# STM32U5Gx register map
File version: 1.0
CPU: CM33 r0p1, little endian, MPU, FPU, 4 interrupt priority bits
Registers are 32-bit, read-write, reset 0x0 unless marked. A register's access mark holds for its fields unless they carry their own. Offsets are from the block's base; [hi:lo] are bit positions; {n}, {i} and the like mark numbered series; 'fields as' and 'values as' point back to an identical list.

## OTG_HS
Base 0x42040000
Same registers: SEC_OTG_HS 0x52040000
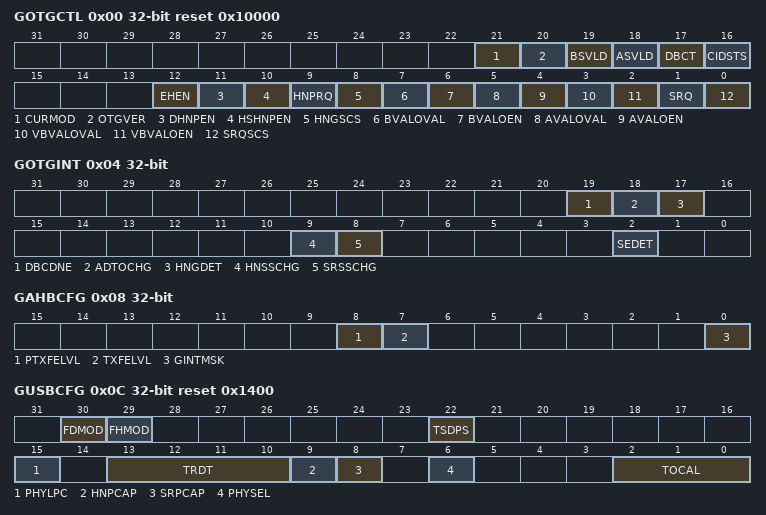
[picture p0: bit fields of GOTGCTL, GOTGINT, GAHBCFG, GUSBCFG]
0x00 GOTGCTL access per field reset 0x10000 — The GOTGCTL register controls the behavior and reflects the status of the OTG function of the core.
  [21] CURMOD ro, [20] OTGVER rw, [19] BSVLD ro, [18] ASVLD ro, [17] DBCT ro, [16] CIDSTS ro, [12] EHEN rw, [11] DHNPEN rw, [10] HSHNPEN rw, [9] HNPRQ rw, [8] HNGSCS ro, [7] BVALOVAL rw, [6] BVALOEN rw, [5] AVALOVAL rw, [4] AVALOEN rw, [3] VBVALOVAL rw, [2] VBVALOEN rw, [1] SRQ rw, [0] SRQSCS ro
0x04 GOTGINT — The application reads this register whenever there is an OTG interrupt and clears the bits in this register to clear the OTG interrupt.
  [19] DBCDNE, [18] ADTOCHG, [17] HNGDET, [9] HNSSCHG, [8] SRSSCHG, [2] SEDET
0x08 GAHBCFG — This register can be used to configure the core after power-on or a change in mode. This register mainly contains AHB system-related configuration parameters. Do not change this register after the initial programming. The application must program this register before starting any transactions on either the AHB or the USB.
  [8] PTXFELVL, [7] TXFELVL, [0] GINTMSK
0x0C GUSBCFG access per field reset 0x1400 — This register can be used to configure the core after power-on or a changing to host mode or device mode. It contains USB and USB-PHY related configuration parameters. The application must program this register before starting any transactions on either the AHB or the USB. Do not make changes to this register after the initial programming.
  [30] FDMOD rw, [29] FHMOD rw, [22] TSDPS rw, [15] PHYLPC rw, [13:10] TRDT rw, [9] HNPCAP rw, [8] SRPCAP rw, [6] PHYSEL ro, [2:0] TOCAL rw
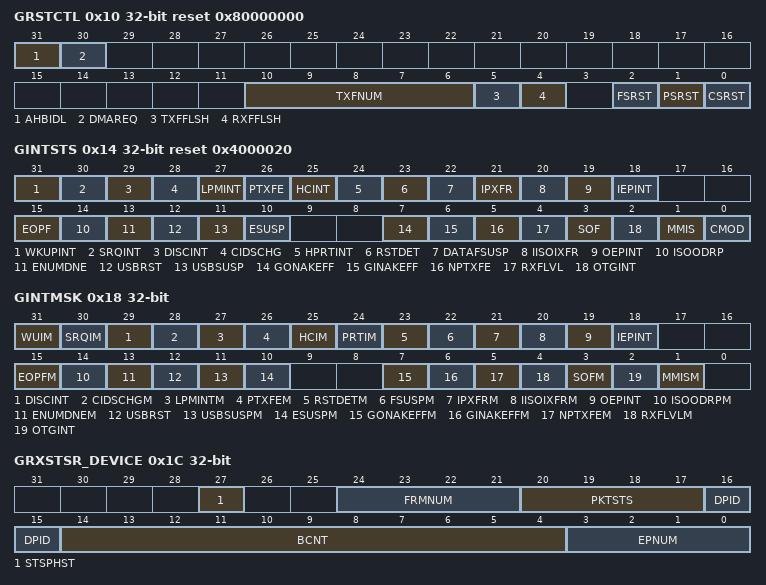
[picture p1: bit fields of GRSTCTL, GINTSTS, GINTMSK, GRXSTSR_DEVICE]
0x10 GRSTCTL access per field reset 0x80000000 — The application uses this register to reset various hardware features inside the core.
  [31] AHBIDL ro, [30] DMAREQ ro, [10:6] TXFNUM rw, [5] TXFFLSH rw, [4] RXFFLSH rw, [2] FSRST rw, [1] PSRST rw, [0] CSRST ro
0x14 GINTSTS access per field reset 0x4000020 — This register interrupts the application for system-level events in the current mode (device mode or host mode). Some of the bits in this register are valid only in host mode, while others are valid in device mode only. This register also indicates the current mode. To clear the interrupt status bits of the rc_w1 type, the application must write 1 into the bit. The FIFO status interrupts are read-only; once software reads from or writes to the FIFO while servicing these interrupts, FIFO interrupt conditions are cleared automatically. The application must clear the GINTSTS register at initialization before unmasking the interrupt bit to avoid any interrupts generated prior to initialization.
  [31] WKUPINT rw, [30] SRQINT rw, [29] DISCINT rw, [28] CIDSCHG rw, [27] LPMINT rw, [26] PTXFE ro, [25] HCINT ro, [24] HPRTINT ro, [23] RSTDET rw, [22] DATAFSUSP rw, [21] IPXFR rw, [20] IISOIXFR rw, [19] OEPINT ro, [18] IEPINT ro, [15] EOPF rw, [14] ISOODRP rw, [13] ENUMDNE rw, [12] USBRST rw, [11] USBSUSP rw, [10] ESUSP rw, [7] GONAKEFF ro, [6] GINAKEFF ro, [5] NPTXFE ro, [4] RXFLVL ro, [3] SOF rw, [2] OTGINT ro, [1] MMIS rw, [0] CMOD ro
0x18 GINTMSK — This register works with the core interrupt register to interrupt the application. When an interrupt bit is masked, the interrupt associated with that bit is not generated. However, the core interrupt (GINTSTS) register bit corresponding to that interrupt is still set.
  [31] WUIM, [30] SRQIM, [29] DISCINT, [28] CIDSCHGM, [27] LPMINTM, [26] PTXFEM, [25] HCIM, [24] PRTIM, [23] RSTDETM, [22] FSUSPM, [21] IPXFRM, [20] IISOIXFRM, [19] OEPINT, [18] IEPINT, [15] EOPFM, [14] ISOODRPM, [13] ENUMDNEM, [12] USBRST, [11] USBSUSPM, [10] ESUSPM, [7] GONAKEFFM, [6] GINAKEFFM, [5] NPTXFEM, [4] RXFLVLM, [3] SOFM, [2] OTGINT, [1] MMISM
0x1C GRXSTSR_DEVICE ro — This description is for register GRXSTSR in Device mode. A read to the receive status debug read register returns the contents of the top of the receive FIFO. The core ignores the receive status read when the receive FIFO is empty and returns a value of 0x00000000.
  [27] STSPHST, [24:21] FRMNUM, [20:17] PKTSTS, [16:15] DPID, [14:4] BCNT, [3:0] EPNUM
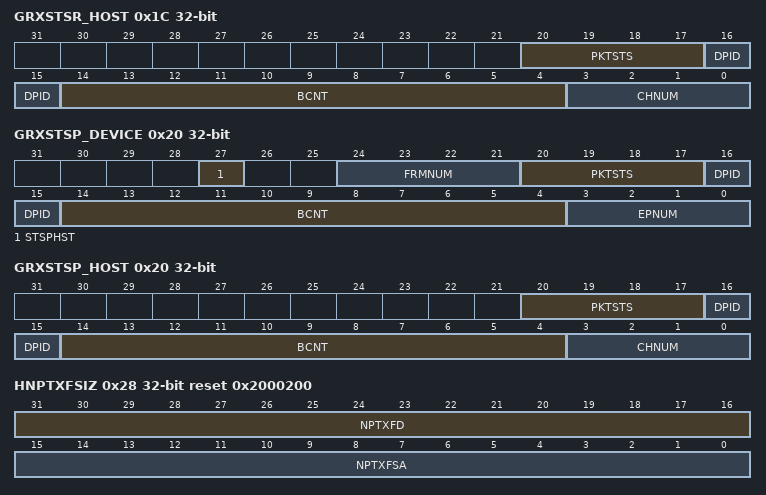
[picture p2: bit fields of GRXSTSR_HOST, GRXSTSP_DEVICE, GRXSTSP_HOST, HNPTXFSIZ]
0x1C GRXSTSR_HOST ro (alternate view of GRXSTSR_DEVICE) — This description is for register GRXSTSR in Host mode
  [20:17] PKTSTS, [16:15] DPID, [14:4] BCNT, [3:0] CHNUM
0x20 GRXSTSP_DEVICE ro — This description is for register GRXSTSP in Device mode. Similarly to GRXSTSR (receive status debug read register) where a read returns the contents of the top of the receive FIFO, a read to GRXSTSP (receive status read and pop register) additionally pops the top data entry out of the Rx FIFO. The core ignores the receive status pop/read when the receive FIFO is empty and returns a value of 0x00000000. The application must only pop the receive status FIFO when the receive FIFO non-empty bit of the core interrupt register (RXFLVL bit in GINTSTS) is asserted.
  fields as GRXSTSR_DEVICE
0x20 GRXSTSP_HOST ro (alternate view of GRXSTSP_DEVICE) — This description is for register GRXSTSP in HOST mode
  [20:17] PKTSTS, [16:15] DPID, [14:4] BCNT, [3:0] CHNUM
0x24 GRXFSIZ reset 0x400 — The application can program the RAM size that must be allocated to the Rx FIFO.
  [15:0] RXFD
0x28 HNPTXFSIZ reset 0x2000200 — Host mode
  [31:16] NPTXFD, [15:0] NPTXFSA
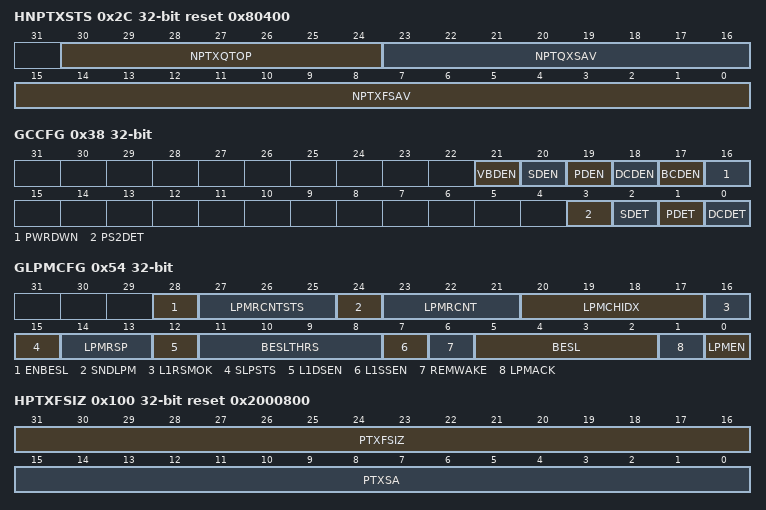
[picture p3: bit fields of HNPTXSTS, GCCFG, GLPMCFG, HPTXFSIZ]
0x2C HNPTXSTS ro reset 0x80400 — In device mode, this register is not valid. This read-only register contains the free space information for the non-periodic Tx FIFO and the non-periodic transmit request queue.
  [30:24] NPTXQTOP, [23:16] NPTQXSAV, [15:0] NPTXFSAV
0x38 GCCFG access per field — OTG general core configuration register
  [21] VBDEN rw, [20] SDEN rw, [19] PDEN rw, [18] DCDEN rw, [17] BCDEN rw, [16] PWRDWN rw, [3] PS2DET ro, [2] SDET ro, [1] PDET ro, [0] DCDET ro
0x3C CID reset 0x3100 — This is a register containing the Product ID as reset value.
  [31:0] PRODUCT_ID
0x54 GLPMCFG access per field — OTG core LPM configuration register
  [28] ENBESL rw, [27:25] LPMRCNTSTS ro, [24] SNDLPM rw, [23:21] LPMRCNT rw, [20:17] LPMCHIDX rw, [16] L1RSMOK ro, [15] SLPSTS ro, [14:13] LPMRSP ro, [12] L1DSEN rw, [11:8] BESLTHRS rw, [7] L1SSEN rw, [6] REMWAKE rw, [5:2] BESL rw, [1] LPMACK rw, [0] LPMEN rw
0x100 HPTXFSIZ reset 0x2000800 — OTG host periodic transmit FIFO size register
  [31:16] PTXFSIZ, [15:0] PTXSA
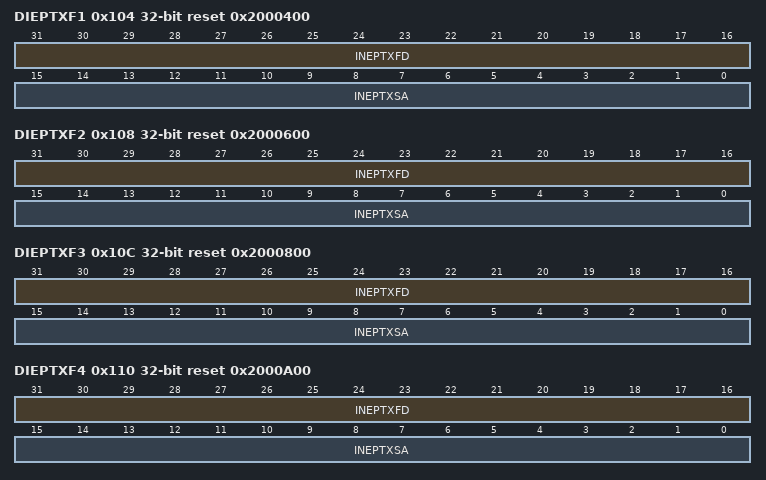
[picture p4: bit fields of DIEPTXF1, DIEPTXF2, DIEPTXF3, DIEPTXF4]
0x104 DIEPTXF1 reset 0x2000400 — OTG device IN endpoint transmit FIFO 1 size register
  [31:16] INEPTXFD, [15:0] INEPTXSA
0x108 DIEPTXF2 reset 0x2000600 — OTG device IN endpoint transmit FIFO 2 size register
  [31:16] INEPTXFD, [15:0] INEPTXSA
0x10C DIEPTXF3 reset 0x2000800 — OTG device IN endpoint transmit FIFO 3 size register
  [31:16] INEPTXFD, [15:0] INEPTXSA
0x110 DIEPTXF4 reset 0x2000A00 — OTG device IN endpoint transmit FIFO 4 size register
  [31:16] INEPTXFD, [15:0] INEPTXSA
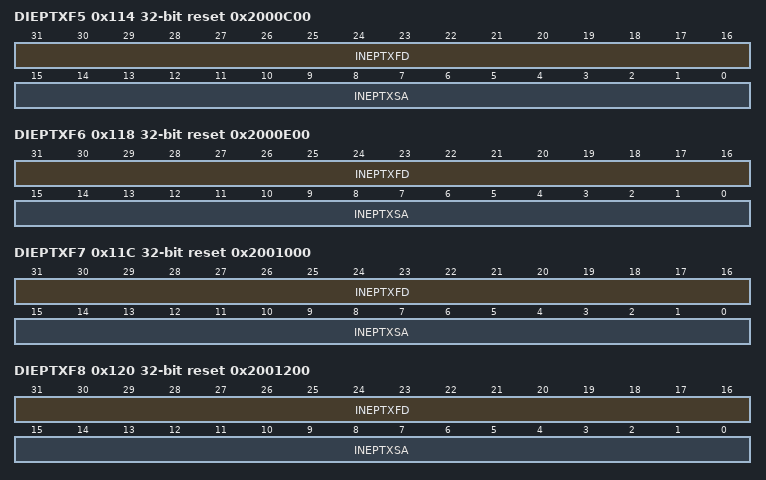
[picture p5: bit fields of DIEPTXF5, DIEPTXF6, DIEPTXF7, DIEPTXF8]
0x114 DIEPTXF5 reset 0x2000C00 — OTG device IN endpoint transmit FIFO 5 size register
  [31:16] INEPTXFD, [15:0] INEPTXSA
0x118 DIEPTXF6 reset 0x2000E00 — OTG device IN endpoint transmit FIFO 6 size register
  [31:16] INEPTXFD, [15:0] INEPTXSA
0x11C DIEPTXF7 reset 0x2001000 — OTG device IN endpoint transmit FIFO 7 size register
  [31:16] INEPTXFD, [15:0] INEPTXSA
0x120 DIEPTXF8 reset 0x2001200 — OTG device IN endpoint transmit FIFO 8 size register
  [31:16] INEPTXFD, [15:0] INEPTXSA
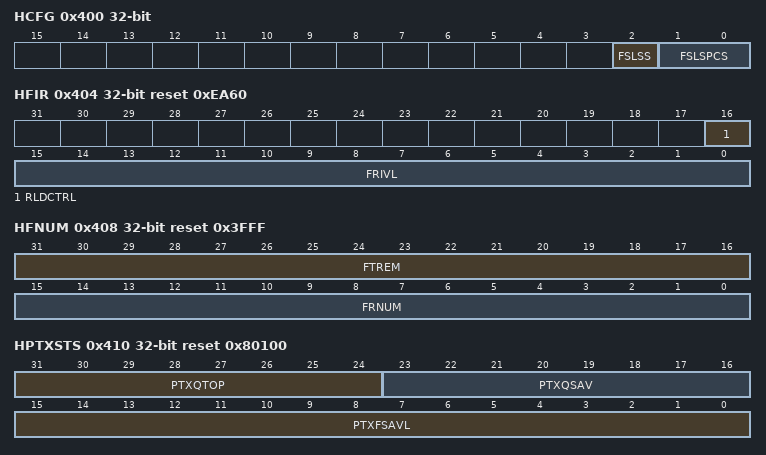
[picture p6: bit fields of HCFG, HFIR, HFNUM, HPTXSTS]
0x400 HCFG access per field — This register configures the core after power-on. Do not make changes to this register after initializing the host.
  [2] FSLSS ro, [1:0] FSLSPCS rw
0x404 HFIR reset 0xEA60 — This register stores the frame interval information for the current speed to which the OTG controller has enumerated.
  [16] RLDCTRL, [15:0] FRIVL
0x408 HFNUM ro reset 0x3FFF — This register indicates the current frame number. It also indicates the time remaining (in terms of the number of PHY clocks) in the current frame.
  [31:16] FTREM, [15:0] FRNUM
0x410 HPTXSTS ro reset 0x80100 — This read-only register contains the free space information for the periodic Tx FIFO and the periodic transmit request queue.
  [31:24] PTXQTOP, [23:16] PTXQSAV, [15:0] PTXFSAVL
0x414 HAINT ro — When a significant event occurs on a channel, the host all channels interrupt register interrupts the application using the host channels interrupt bit of the core interrupt register (HCINT bit in GINTSTS). This is shown in Figure724. There is one interrupt bit per channel, up to a maximum of 16 bits. Bits in this register are set and cleared when the application sets and clears bits in the corresponding host channel-x interrupt register.
  [15:0] HAINT
0x418 HAINTMSK — The host all channel interrupt mask register works with the host all channel interrupt register to interrupt the application when an event occurs on a channel. There is one interrupt mask bit per channel, up to a maximum of 16 bits.
  [15:0] HAINTM
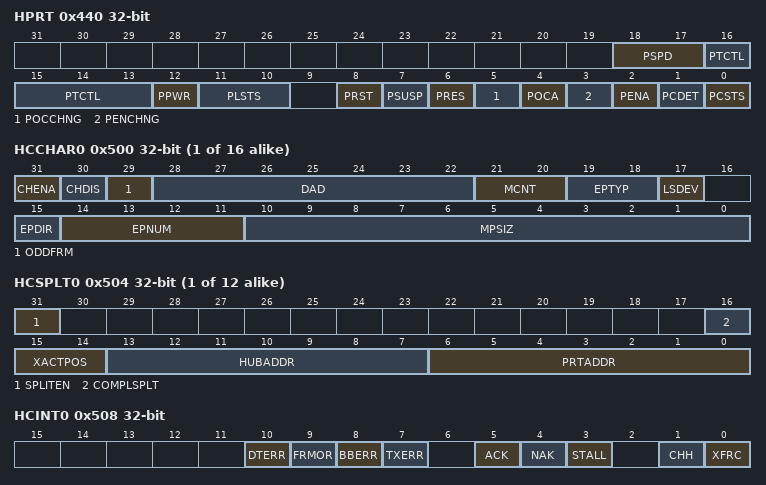
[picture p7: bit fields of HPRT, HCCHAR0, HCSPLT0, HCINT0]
0x440 HPRT access per field — This register is available only in host mode. Currently, the OTG host supports only one port. A single register holds USB port-related information such as USB reset, enable, suspend, resume, connect status, and test mode for each port. It is shown in Figure724. The rc_w1 bits in this register can trigger an interrupt to the application through the host port interrupt bit of the core interrupt register (HPRTINT bit in GINTSTS). On a port interrupt, the application must read this register and clear the bit that caused the interrupt. For the rc_w1 bits, the application must write a 1 to the bit to clear the interrupt.
  [18:17] PSPD ro, [16:13] PTCTL rw, [12] PPWR rw, [11:10] PLSTS ro, [8] PRST rw, [7] PSUSP rw, [6] PRES rw, [5] POCCHNG rw, [4] POCA ro, [3] PENCHNG rw, [2] PENA rw, [1] PCDET rw, [0] PCSTS ro
{0x500+0x20*i} HCCHAR{i} (i=0..15) — OTG host channel {i} characteristics register
  [31] CHENA, [30] CHDIS, [29] ODDFRM, [28:22] DAD, [21:20] MCNT, [19:18] EPTYP, [17] LSDEV, [15] EPDIR, [14:11] EPNUM, [10:0] MPSIZ
{0x504+0x20*i} HCSPLT{i} (i=0..11) — OTG host channel {i} split control register
  [31] SPLITEN — Split enable The application sets this bit to indicate that this channel is enabled to perform split transactions.
  [16] COMPLSPLT — Do complete split The application sets this bit to request the OTG host to perform a complete split transaction.
  [15:14] XACTPOS — Transaction position This field is used to determine whether to send all, first, middle, or last payloads with each OUT transaction.
    3=All. This is the entire data payload of this transaction (which is less than or equal to 188 bytes); 2=Begin. This is the first data payload of this transaction (which is larger than 188 bytes); 0=Mid. This is the middle payload of this transaction (which is larger than 188 bytes); 1=End. This is the last payload of this transaction (which is larger than 188 bytes)
  [13:7] HUBADDR — Hub address This field holds the device address of the transaction translatorâs hub.
  [6:0] PRTADDR — Port address This field is the port number of the recipient transaction translator.
0x508 HCINT0 — This register indicates the status of a channel with respect to USB- and AHB-related events. It is shown in Figure724. The application must read this register when the host channels interrupt bit in the core interrupt register (HCINT bit in GINTSTS) is set. Before the application can read this register, it must first read the host all channels interrupt (HAINT) register to get the exact channel number for the host channel-x interrupt register. The application must clear the appropriate bit in this register to clear the corresponding bits in the HAINT and GINTSTS registers.
  [10] DTERR, [9] FRMOR, [8] BBERR, [7] TXERR, [5] ACK, [4] NAK, [3] STALL, [1] CHH, [0] XFRC
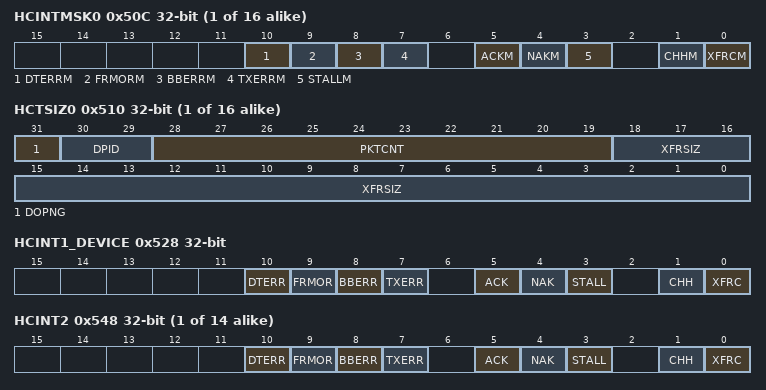
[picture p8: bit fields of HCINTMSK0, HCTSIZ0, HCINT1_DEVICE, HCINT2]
{0x50C+0x20*i} HCINTMSK{i} (i=0..15) — This register reflects the mask for each channel status described in the previous section.
  [10] DTERRM, [9] FRMORM, [8] BBERRM, [7] TXERRM, [5] ACKM, [4] NAKM, [3] STALLM, [1] CHHM, [0] XFRCM
{0x510+0x20*i} HCTSIZ{i} (i=0..15) — OTG host channel {i} transfer size register
  [31] DOPNG, [30:29] DPID, [28:19] PKTCNT, [18:0] XFRSIZ
{0x514+0x20*i} HCDMA{i} (i=0..15) — OTG host channel {i} DMA address register
  [31:0] DMAADDR — DMA address This field holds the start address in the external memory from which the data for the endpoint must be fetched or to which it must be stored. This register is incremented on every AHB transaction.
0x528 HCINT1_DEVICE — This register indicates the status of a channel with respect to USB- and AHB-related events. It is shown in Figure724. The application must read this register when the host channels interrupt bit in the core interrupt register (HCINT bit in GINTSTS) is set. Before the application can read this register, it must first read the host all channels interrupt (HAINT) register to get the exact channel number for the host channel-x interrupt register. The application must clear the appropriate bit in this register to clear the corresponding bits in the HAINT and GINTSTS registers.
  fields as HCINT0
{0x508+0x20*i} HCINT{i} (i=2..15) — This register indicates the status of a channel with respect to USB- and AHB-related events. It is shown in Figure724. The application must read this register when the host channels interrupt bit in the core interrupt register (HCINT bit in GINTSTS) is set. Before the application can read this register, it must first read the host all channels interrupt (HAINT) register to get the exact channel number for the host channel-x interrupt register. The application must clear the appropriate bit in this register to clear the corresponding bits in the HAINT and GINTSTS registers.
  fields as HCINT0
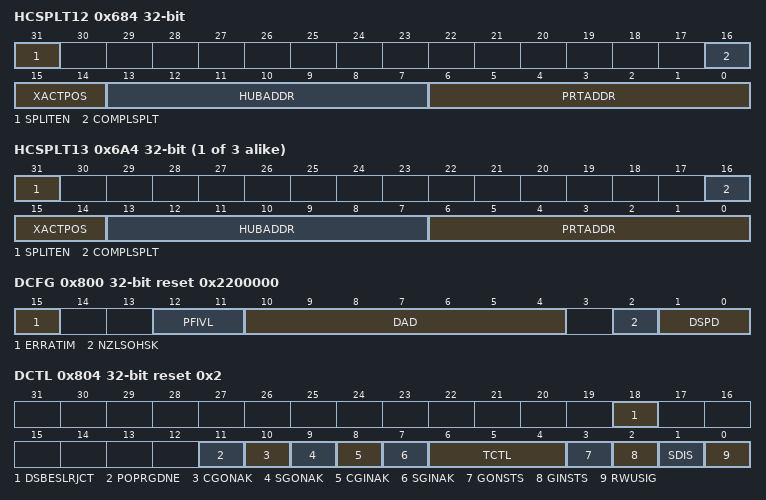
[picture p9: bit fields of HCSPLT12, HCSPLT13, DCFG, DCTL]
0x684 HCSPLT12 — OTG host channel 0 split control register
  fields as HCSPLT0
{0x504+0x20*i} HCSPLT{i} (i=13..15) — OTG host channel {i} split control register
  fields as HCSPLT0
0x800 DCFG reset 0x2200000 — This register configures the core in device mode after power-on or after certain control commands or enumeration. Do not make changes to this register after initial programming.
  [15] ERRATIM, [12:11] PFIVL, [10:4] DAD, [2] NZLSOHSK, [1:0] DSPD
0x804 DCTL access per field reset 0x2 — OTG device control register
  [18] DSBESLRJCT rw, [11] POPRGDNE rw, [10] CGONAK wo, [9] SGONAK wo, [8] CGINAK wo, [7] SGINAK wo, [6:4] TCTL rw, [3] GONSTS ro, [2] GINSTS ro, [1] SDIS rw, [0] RWUSIG rw
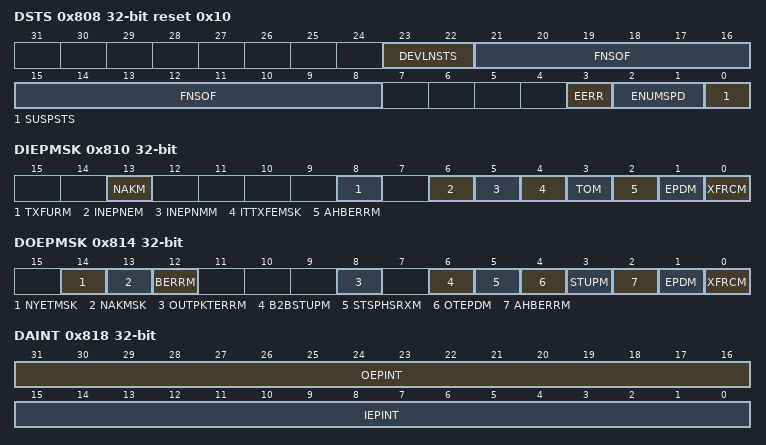
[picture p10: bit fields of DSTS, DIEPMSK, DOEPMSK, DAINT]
0x808 DSTS ro reset 0x10 — This register indicates the status of the core with respect to USB-related events. It must be read on interrupts from the device all interrupts (DAINT) register.
  [23:22] DEVLNSTS, [21:8] FNSOF, [3] EERR, [2:1] ENUMSPD, [0] SUSPSTS
0x810 DIEPMSK — This register works with each of the DIEPINTx registers for all endpoints to generate an interrupt per IN endpoint. The IN endpoint interrupt for a specific status in the DIEPINTx register can be masked by writing to the corresponding bit in this register. Status bits are masked by default.
  [13] NAKM, [8] TXFURM, [6] INEPNEM, [5] INEPNMM, [4] ITTXFEMSK, [3] TOM, [2] AHBERRM, [1] EPDM, [0] XFRCM
0x814 DOEPMSK — This register works with each of the DOEPINTx registers for all endpoints to generate an interrupt per OUT endpoint. The OUT endpoint interrupt for a specific status in the DOEPINTx register can be masked by writing into the corresponding bit in this register. Status bits are masked by default.
  [14] NYETMSK, [13] NAKMSK, [12] BERRM, [8] OUTPKTERRM, [6] B2BSTUPM, [5] STSPHSRXM, [4] OTEPDM, [3] STUPM, [2] AHBERRM, [1] EPDM, [0] XFRCM
0x818 DAINT ro — When a significant event occurs on an endpoint, a DAINT register interrupts the application using the device OUT endpoints interrupt bit or device IN endpoints interrupt bit of the GINTSTS register (OEPINT or IEPINT in GINTSTS, respectively). There is one interrupt bit per endpoint, up to a maximum of 16 bits for OUT endpoints and 16 bits for IN endpoints. For a bidirectional endpoint, the corresponding IN and OUT interrupt bits are used. Bits in this register are set and cleared when the application sets and clears bits in the corresponding device endpoint-x interrupt register (DIEPINTx/DOEPINTx).
  [31:16] OEPINT, [15:0] IEPINT
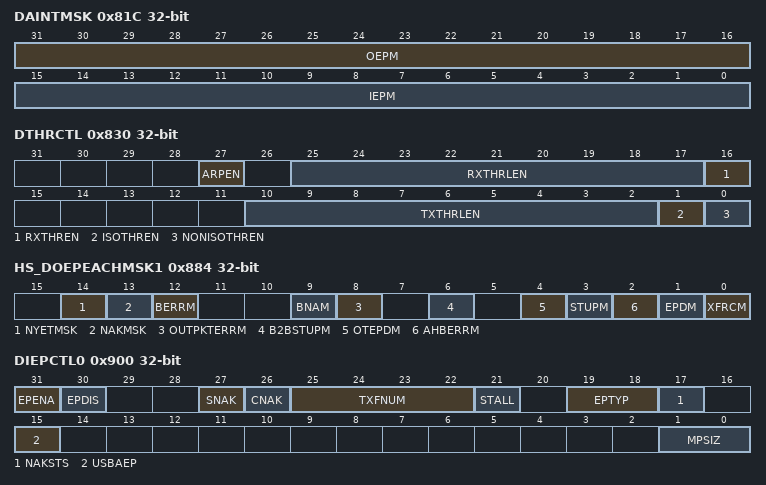
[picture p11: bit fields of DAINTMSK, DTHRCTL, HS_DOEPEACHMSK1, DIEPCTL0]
0x81C DAINTMSK — The DAINTMSK register works with the device endpoint interrupt register to interrupt the application when an event occurs on a device endpoint. However, the DAINT register bit corresponding to that interrupt is still set.
  [31:16] OEPM, [15:0] IEPM
0x828 DVBUSDIS reset 0x17D7 — This register specifies the VBUS discharge time after VBUS pulsing during SRP.
  [15:0] VBUSDT
0x82C DVBUSPULSE reset 0x5B8 — This register specifies the VBUS pulsing time during SRP.
  [15:0] DVBUSP
0x830 DTHRCTL — OTG device threshold control register
  [27] ARPEN — Arbiter parking enable This bit controls internal DMA arbiter parking for IN endpoints. When thresholding is enabled and this bit is set to one, then the arbiter parks on the IN endpoint for which there is a token received on the USB. This is done to avoid getting into underrun conditions. By default parking is enabled.
  [25:17] RXTHRLEN — Receive threshold length This field specifies the receive thresholding size in 32-bit words. This field also specifies the amount of data received on the USB before the core can start transmitting on the AHB. The threshold length has to be at least eight 32-bit words. The recommended value for RXTHRLEN is to be the same as the programmed AHB burst length (HBSTLEN bit in OTG_GAHBCFG).
  [16] RXTHREN — Receive threshold enable When this bit is set, the core enables thresholding in the receive direction.
  [10:2] TXTHRLEN — Transmit threshold length This field specifies the transmit thresholding size in 32-bit words. This field specifies the amount of data in bytes to be in the corresponding endpoint transmit FIFO, before the core can start transmitting on the USB. The threshold length has to be at least eight 32-bit words. This field controls both isochronous and nonisochronous IN endpoint thresholds. The recommended value for TXTHRLEN is to be the same as the programmed AHB burst length (HBSTLEN bit in OTG_GAHBCFG).
  [1] ISOTHREN — ISO IN endpoint threshold enable When this bit is set, the core enables thresholding for isochronous IN endpoints.
  [0] NONISOTHREN — Nonisochronous IN endpoints threshold enable When this bit is set, the core enables thresholding for nonisochronous IN endpoints.
0x834 DIEPEMPMSK — This register is used to control the IN endpoint FIFO empty interrupt generation (TXFE_DIEPINTx).
  [15:0] INEPTXFEM
0x884 HS_DOEPEACHMSK1 — OTG device each OUT endpoint-1 interrupt mask register
  [14] NYETMSK, [13] NAKMSK, [12] BERRM, [9] BNAM, [8] OUTPKTERRM, [6] B2BSTUPM, [4] OTEPDM, [3] STUPM, [2] AHBERRM, [1] EPDM, [0] XFRCM
0x900 DIEPCTL0 access per field — The application uses this register to control the behavior of each logical endpoint other than endpoint 0.
  [31] EPENA rw, [30] EPDIS rw, [27] SNAK wo, [26] CNAK wo, [25:22] TXFNUM rw, [21] STALL rw, [19:18] EPTYP rw, [17] NAKSTS ro, [15] USBAEP ro, [1:0] MPSIZ rw
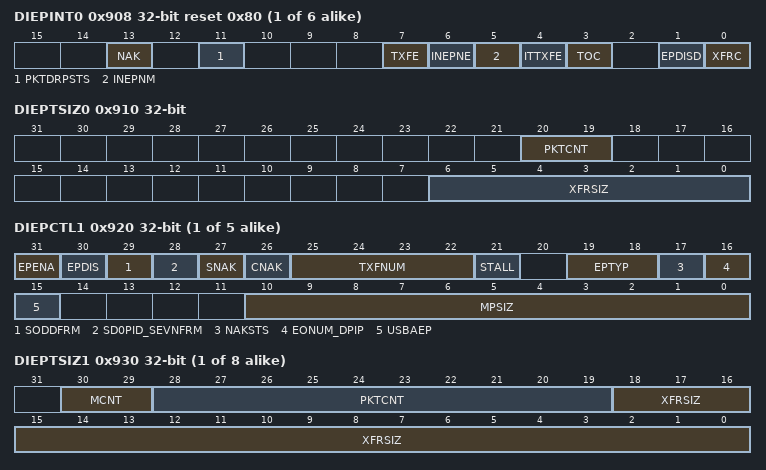
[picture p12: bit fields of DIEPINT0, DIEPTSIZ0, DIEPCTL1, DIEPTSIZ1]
{0x908+0x20*i} DIEPINT{i} access per field reset 0x80 (i=0..5) — This register indicates the status of an endpoint with respect to USB- and AHB-related events. It is shown in Figure724. The application must read this register when the IN endpoints interrupt bit of the core interrupt register (IEPINT in GINTSTS) is set. Before the application can read this register, it must first read the device all endpoints interrupt (DAINT) register to get the exact endpoint number for the device endpoint-x interrupt register. The application must clear the appropriate bit in this register to clear the corresponding bits in the DAINT and GINTSTS registers.
  [13] NAK rw, [11] PKTDRPSTS rw, [7] TXFE ro, [6] INEPNE ro, [5] INEPNM rw, [4] ITTXFE rw, [3] TOC rw, [1] EPDISD rw, [0] XFRC rw
0x910 DIEPTSIZ0 — The application must modify this register before enabling endpoint 0.
  [20:19] PKTCNT, [6:0] XFRSIZ
{0x918+0x20*i} DTXFSTS{i} ro reset 0x200 (i=0..5) — This read-only register contains the free space information for the device IN endpoint Tx FIFO.
  [15:0] INEPTFSAV
{0x900+0x20*i} DIEPCTL{i} access per field (i=1..5) — The application uses this register to control the behavior of each logical endpoint other than endpoint 0.
  [31] EPENA rw, [30] EPDIS rw, [29] SODDFRM wo, [28] SD0PID_SEVNFRM wo, [27] SNAK wo, [26] CNAK wo, [25:22] TXFNUM rw, [21] STALL rw, [19:18] EPTYP rw, [17] NAKSTS ro, [16] EONUM_DPIP ro, [15] USBAEP rw, [10:0] MPSIZ rw
{0x910+0x20*i} DIEPTSIZ{i} (i=1..8) — The application must modify this register before enabling the endpoint. Once the endpoint is enabled using the endpoint enable bit in the DIEPCTLx registers (EPENA bit in DIEPCTLx), the core modifies this register. The application can only read this register once the core has cleared the endpoint enable bit.
  [30:29] MCNT, [28:19] PKTCNT, [18:0] XFRSIZ
{0x914+0x20*i} DIEPDMA{i} (i=1..8) — OTG device IN endpoint {i} DMA address register
  [31:0] DMAADDR
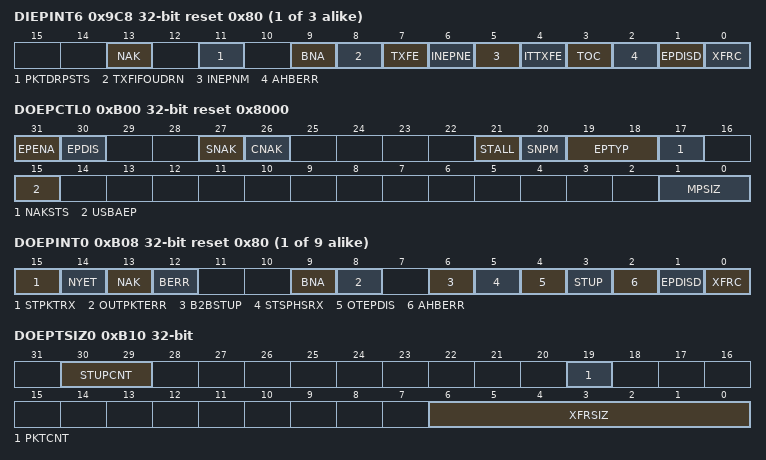
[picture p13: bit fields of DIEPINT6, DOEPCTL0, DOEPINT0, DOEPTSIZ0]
{0x908+0x20*i} DIEPINT{i} access per field reset 0x80 (i=6..8) — This register indicates the status of an endpoint with respect to USB- and AHB-related events. It is shown in Figure724. The application must read this register when the IN endpoints interrupt bit of the core interrupt register (IEPINT in GINTSTS) is set. Before the application can read this register, it must first read the device all endpoints interrupt (DAINT) register to get the exact endpoint number for the device endpoint-x interrupt register. The application must clear the appropriate bit in this register to clear the corresponding bits in the DAINT and GINTSTS registers.
  [13] NAK rw, [11] PKTDRPSTS rw, [9] BNA rw, [8] TXFIFOUDRN rw, [7] TXFE ro, [6] INEPNE ro, [5] INEPNM rw, [4] ITTXFE rw, [3] TOC rw, [2] AHBERR rw, [1] EPDISD rw, [0] XFRC rw
0xB00 DOEPCTL0 access per field reset 0x8000 — This section describes the DOEPCTL0 register.
  [31] EPENA wo, [30] EPDIS ro, [27] SNAK wo, [26] CNAK wo, [21] STALL rw, [20] SNPM rw, [19:18] EPTYP ro, [17] NAKSTS ro, [15] USBAEP ro, [1:0] MPSIZ ro
{0xB08+0x20*i} DOEPINT{i} reset 0x80 (i=0..8) — This register indicates the status of an endpoint with respect to USB- and AHB-related events. It is shown in Figure724. The application must read this register when the OUT endpoints interrupt bit of the GINTSTS register (OEPINT bit in GINTSTS) is set. Before the application can read this register, it must first read the DAINT register to get the exact endpoint number for the DOEPINTx register. The application must clear the appropriate bit in this register to clear the corresponding bits in the DAINT and GINTSTS registers.
  [15] STPKTRX, [14] NYET, [13] NAK, [12] BERR, [9] BNA, [8] OUTPKTERR, [6] B2BSTUP, [5] STSPHSRX, [4] OTEPDIS, [3] STUP, [2] AHBERR, [1] EPDISD, [0] XFRC
0xB10 DOEPTSIZ0 — The application must modify this register before enabling endpoint 0.
  [30:29] STUPCNT, [19] PKTCNT, [6:0] XFRSIZ
{0xB14+0x20*i} DOEPDMA{i} (i=0..8) — OTG device OUT endpoint {i} DMA address register
  [31:0] DMAADDR
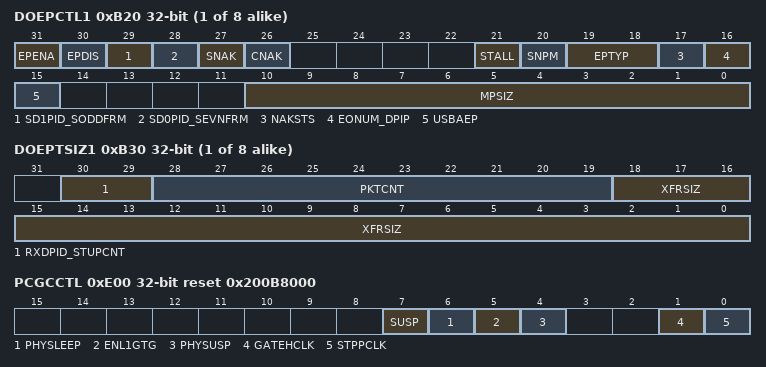
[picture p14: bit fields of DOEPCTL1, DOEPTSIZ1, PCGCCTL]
{0xB00+0x20*i} DOEPCTL{i} access per field (i=1..8) — The application uses this register to control the behavior of each logical endpoint other than endpoint 0.
  [31] EPENA rw, [30] EPDIS rw, [29] SD1PID_SODDFRM wo, [28] SD0PID_SEVNFRM wo, [27] SNAK wo, [26] CNAK wo, [21] STALL rw, [20] SNPM rw, [19:18] EPTYP rw, [17] NAKSTS ro, [16] EONUM_DPIP ro, [15] USBAEP rw, [10:0] MPSIZ rw
{0xB10+0x20*i} DOEPTSIZ{i} (i=1..8) — The application must modify this register before enabling the endpoint. Once the endpoint is enabled using endpoint enable bit of the DOEPCTLx registers (EPENA bit in DOEPCTLx), the core modifies this register. The application can only read this register once the core has cleared the endpoint enable bit.
  [30:29] RXDPID_STUPCNT, [28:19] PKTCNT, [18:0] XFRSIZ
0xE00 PCGCCTL access per field reset 0x200B8000 — This register is available in host and device modes.
  [7] SUSP ro, [6] PHYSLEEP ro, [5] ENL1GTG rw, [4] PHYSUSP ro, [1] GATEHCLK rw, [0] STPPCLK rw
